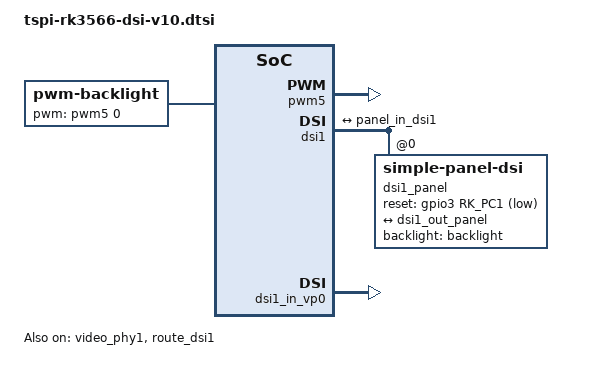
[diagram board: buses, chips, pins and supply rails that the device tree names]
/*********************************************************************
 *           立创开发板不靠卖板赚钱，以培养中国工程师为己任  
 *         泰山派软硬件资料与相关扩展板软硬件资料官网全部开源
 *                      开发板官网：www.lckfb.com            
 *                     立创论坛：oshwhub.com/forum           
 *            关注B站：【立创开发板】，掌握我们的最新动态！  
 *********************************************************************
 * 文件名：tspi-rk3566-dsi-v10.dtsi
 * 描述：mipi 屏幕
 * 更新:
 * 时间          作者           联系           说明
 * 2023-09-13   吴才成    1378913492@qq.com   v1.0.0
 *********************************************************************/
/ {
	backlight: backlight {
		compatible = "pwm-backlight";
		pwms = <&pwm5 0 25000 0>;
		brightness-levels = <
			  0  20  20  21  21  22  22  23
			 23  24  24  25  25  26  26  27
			 27  28  28  29  29  30  30  31
			 31  32  32  33  33  34  34  35
			 35  36  36  37  37  38  38  39
			 40  41  42  43  44  45  46  47
			 48  49  50  51  52  53  54  55
			 56  57  58  59  60  61  62  63
			 64  65  66  67  68  69  70  71
			 72  73  74  75  76  77  78  79
			 80  81  82  83  84  85  86  87
			 88  89  90  91  92  93  94  95
			 96  97  98  99 100 101 102 103
			104 105 106 107 108 109 110 111
			112 113 114 115 116 117 118 119
			120 121 122 123 124 125 126 127
			128 129 130 131 132 133 134 135
			136 137 138 139 140 141 142 143
			144 145 146 147 148 149 150 151
			152 153 154 155 156 157 158 159
			160 161 162 163 164 165 166 167
			168 169 170 171 172 173 174 175
			176 177 178 179 180 181 182 183
			184 185 186 187 188 189 190 191
			192 193 194 195 196 197 198 199
			200 201 202 203 204 205 206 207
			208 209 210 211 212 213 214 215
			216 217 218 219 220 221 222 223
			224 225 226 227 228 229 230 231
			232 233 234 235 236 237 238 239
			240 241 242 243 244 245 246 247
			248 249 250 251 252 253 254 255
		>;
		default-brightness-level = <255>;
	};
};

&pwm5 {
	status = "okay";
};


&pinctrl {
	dsi1 {
		dsi1_rst_gpio: dsi1-rst-gpio {
			rockchip,pins = <3 RK_PC1 RK_FUNC_GPIO &pcfg_pull_none>;
		};
	};
};

/*
 * video_phy1 needs to be enabled
 * when dsi1 is enabled
 */
&dsi1 {
	status = "okay";
};

&dsi1_in_vp0 {
	status = "okay";
};

&dsi1_in_vp1 {
	status = "disabled";
};

&video_phy1 {
	status = "okay";
};

&route_dsi1 {
	status = "okay";//wucaicheng mipi okay
	connect = <&vp0_out_dsi1>;
};

//默认 8寸800x1280
&dsi1 {
	status = "okay";
	rockchip,lane-rate = <480>;
	dsi1_panel: panel@0 {
		status = "okay";
		compatible = "simple-panel-dsi";
		reset-gpios = <&gpio3 RK_PC1 GPIO_ACTIVE_LOW>;
		pinctrl-names = "default";
		pinctrl-0 = <&dsi1_rst_gpio>;
		reg = <0>;
		backlight = <&backlight>;
		reset-delay-ms = <10>;
		enable-delay-ms = <120>;
		prepare-delay-ms = <20>;
		unprepare-delay-ms = <20>;
		disable-delay-ms = <50>;
		dsi,flags = <(MIPI_DSI_MODE_VIDEO | MIPI_DSI_MODE_VIDEO_BURST |
			MIPI_DSI_MODE_LPM | MIPI_DSI_MODE_EOT_PACKET)>;
		dsi,format = <MIPI_DSI_FMT_RGB888>;
		dsi,lanes  = <4>;
		panel-init-sequence = [
			15 00 02 E0 00
			15 00 02 E1 93
			15 00 02 E2 65
			15 00 02 E3 F8
			15 00 02 80 03
			15 00 02 E0 01
			15 00 02 00 00
			15 00 02 01 3C
			15 00 02 03 10
			15 00 02 04 38
			15 00 02 0C 74
			15 00 02 17 00
			15 00 02 18 E7
			15 00 02 19 01
			15 00 02 1A 00
			15 00 02 1B E7
			15 00 02 1C 01
			15 00 02 24 FE
			15 00 02 35 23
			15 00 02 37 09
			15 00 02 38 04
			15 00 02 39 00
			15 00 02 3A 01
			15 00 02 3C 70
			15 00 02 3D FF
			15 00 02 3E FF
			15 00 02 3F 7F
			15 00 02 40 06
			15 00 02 41 A0
			15 00 02 43 1E
			15 00 02 44 0B
			15 00 02 45 28
			15 00 02 55 02
			15 00 02 57 A9
			15 00 02 59 0A
			15 00 02 5A 2D
			15 00 02 5B 19
			15 00 02 5C 15
			15 00 02 5D 7F
			15 00 02 5E 6E
			15 00 02 5F 5F
			15 00 02 60 53
			15 00 02 61 50
			15 00 02 62 41
			15 00 02 63 44
			15 00 02 64 2C
			15 00 02 65 44
			15 00 02 66 42
			15 00 02 67 40
			15 00 02 68 5B
			15 00 02 69 45
			15 00 02 6A 48
			15 00 02 6B 38
			15 00 02 6C 32
			15 00 02 6D 25
			15 00 02 6E 14
			15 00 02 6F 08
			15 00 02 70 7F
			15 00 02 71 6E
			15 00 02 72 5F
			15 00 02 73 53
			15 00 02 74 50
			15 00 02 75 41
			15 00 02 76 44
			15 00 02 77 2C
			15 00 02 78 44
			15 00 02 79 42
			15 00 02 7A 40
			15 00 02 7B 5B
			15 00 02 7C 45
			15 00 02 7D 48
			15 00 02 7E 38
			15 00 02 7F 32
			15 00 02 80 25
			15 00 02 81 14
			15 00 02 82 08
			15 00 02 E0 02
			15 00 02 00 50
			15 00 02 01 5F
			15 00 02 02 5F
			15 00 02 03 52
			15 00 02 04 77
			15 00 02 05 57
			15 00 02 06 5F
			15 00 02 07 4E
			15 00 02 08 4C
			15 00 02 09 5F
			15 00 02 0A 4A
			15 00 02 0B 48
			15 00 02 0C 5F
			15 00 02 0D 46
			15 00 02 0E 44
			15 00 02 0F 40
			15 00 02 10 5F
			15 00 02 11 5F
			15 00 02 12 5F
			15 00 02 13 5F
			15 00 02 14 5F
			15 00 02 15 5F
			15 00 02 16 51
			15 00 02 17 5F
			15 00 02 18 5F
			15 00 02 19 53
			15 00 02 1A 77
			15 00 02 1B 57
			15 00 02 1C 5F
			15 00 02 1D 4F
			15 00 02 1E 4D
			15 00 02 1F 5F
			15 00 02 20 4B
			15 00 02 21 49
			15 00 02 22 5F
			15 00 02 23 47
			15 00 02 24 45
			15 00 02 25 41
			15 00 02 26 5F
			15 00 02 27 5F
			15 00 02 28 5F
			15 00 02 29 5F
			15 00 02 2A 5F
			15 00 02 2B 5F
			15 00 02 2C 01
			15 00 02 2D 1F
			15 00 02 2E 1F
			15 00 02 2F 13
			15 00 02 30 17
			15 00 02 31 17
			15 00 02 32 1F
			15 00 02 33 0D
			15 00 02 34 0F
			15 00 02 35 1F
			15 00 02 36 05
			15 00 02 37 07
			15 00 02 38 1F
			15 00 02 39 09
			15 00 02 3A 0B
			15 00 02 3B 11
			15 00 02 3C 1F
			15 00 02 3D 1F
			15 00 02 3E 1F
			15 00 02 3F 1F
			15 00 02 40 1F
			15 00 02 41 1F
			15 00 02 42 00
			15 00 02 43 1F
			15 00 02 44 1F
			15 00 02 45 12
			15 00 02 46 17
			15 00 02 47 17
			15 00 02 48 1F
			15 00 02 49 0C
			15 00 02 4A 0E
			15 00 02 4B 1F
			15 00 02 4C 04
			15 00 02 4D 06
			15 00 02 4E 1F
			15 00 02 4F 08
			15 00 02 50 0A
			15 00 02 51 10
			15 00 02 52 1F
			15 00 02 53 1F
			15 00 02 54 1F
			15 00 02 55 1F
			15 00 02 56 1F
			15 00 02 57 1F
			15 00 02 58 40
			15 00 02 5B 10
			15 00 02 5C 06
			15 00 02 5D 40
			15 00 02 5E 00
			15 00 02 5F 00
			15 00 02 60 40
			15 00 02 61 03
			15 00 02 62 04
			15 00 02 63 6C
			15 00 02 64 6C
			15 00 02 65 75
			15 00 02 66 08
			15 00 02 67 B4
			15 00 02 68 08
			15 00 02 69 6C
			15 00 02 6A 6C
			15 00 02 6B 0C
			15 00 02 6D 00
			15 00 02 6E 00
			15 00 02 6F 88
			15 00 02 75 BB
			15 00 02 76 00
			15 00 02 77 05
			15 00 02 78 2A
			15 00 02 E0 04
			15 00 02 00 0E
			15 00 02 02 B3
			15 00 02 09 60
			15 00 02 0E 48
			15 00 02 E0 00
			05 fa 01 11
			05 32 01 29
		];

		panel-exit-sequence = [
			05 00 01 28
			05 00 01 10
		];

		disp_timings1: display-timings {
			native-mode = <&dsi1_timing0>;
			dsi1_timing0: timing0 {
				clock-frequency = <66000000>;
				hactive = <800>;
				vactive = <1280>;
				hfront-porch = <18>;
				hsync-len = <12>;
				hback-porch = <18>;
				vfront-porch = <24>;
				vsync-len = <4>;
				vback-porch = <12>;
				hsync-active = <0>;
				vsync-active = <0>;
				de-active = <0>;
				pixelclk-active = <1>;
			};
		};

		ports {
			#address-cells = <1>;
			#size-cells = <0>;

			port@0 {
				reg = <0>;
				panel_in_dsi1: endpoint {
					remote-endpoint = <&dsi1_out_panel>;
				};
			};
		};
	};

	ports {
		#address-cells = <1>;
		#size-cells = <0>;

		port@1 {
			reg = <1>;
			dsi1_out_panel: endpoint {
				remote-endpoint = <&panel_in_dsi1>;
			};
		};
	};

};

// &dsi1 {
// 	status = "okay";
// 	rockchip,lane-rate = <1000>;
// 	dsi1_panel: panel@0 {
// 		status = "okay";
// 		compatible = "simple-panel-dsi";
// 		reset-gpios = <&gpio3 RK_PC1 GPIO_ACTIVE_LOW>;
// 		pinctrl-names = "default";
// 		pinctrl-0 = <&dsi1_rst_gpio>;
// 		reg = <0>;
// 		backlight = <&backlight>;
// 		reset-delay-ms = <100>;
// 		enable-delay-ms = <120>;
// 		prepare-delay-ms = <20>;
// 		unprepare-delay-ms = <20>;
// 		disable-delay-ms = <100>;
// 		dsi,flags = <(MIPI_DSI_MODE_VIDEO | MIPI_DSI_MODE_VIDEO_BURST |
// 			MIPI_DSI_MODE_LPM | MIPI_DSI_MODE_EOT_PACKET)>;
// 		dsi,format = <MIPI_DSI_FMT_RGB888>;
// 		dsi,lanes  = <4>;
// 		panel-init-sequence = [
// 			15 00 02 B0 01
// 			15 00 02 C3 4F
// 			15 00 02 C4 40
// 			15 00 02 C5 40
// 			15 00 02 C6 40
// 			15 00 02 C7 40
// 			15 00 02 C8 4D
// 			15 00 02 C9 52
// 			15 00 02 CA 51
// 			15 00 02 CD 5D
// 			15 00 02 CE 5B
// 			15 00 02 CF 4B
// 			15 00 02 D0 49
// 			15 00 02 D1 47
// 			15 00 02 D2 45
// 			15 00 02 D3 41
// 			15 00 02 D7 50
// 			15 00 02 D8 40
// 			15 00 02 D9 40
// 			15 00 02 DA 40
// 			15 00 02 DB 40
// 			15 00 02 DC 4E
// 			15 00 02 DD 52
// 			15 00 02 DE 51
// 			15 00 02 E1 5E
// 			15 00 02 E2 5C
// 			15 00 02 E3 4C
// 			15 00 02 E4 4A
// 			15 00 02 E5 48
// 			15 00 02 E6 46
// 			15 00 02 E7 42
// 			15 00 02 B0 03
// 			15 00 02 BE 03
// 			15 00 02 CC 44
// 			15 00 02 C8 07
// 			15 00 02 C9 05
// 			15 00 02 CA 42
// 			15 00 02 CD 3E
// 			15 00 02 CF 60
// 			15 00 02 D2 04
// 			15 00 02 D3 04
// 			15 00 02 D4 01
// 			15 00 02 D5 00
// 			15 00 02 D6 03
// 			15 00 02 D7 04
// 			15 00 02 D9 01
// 			15 00 02 DB 01
// 			15 00 02 E4 F0
// 			15 00 02 E5 0A
// 			15 00 02 B0 00
// 			15 00 02 B1 08
// 			15 00 02 BD 54
// 			15 00 02 C2 06
// 			15 00 02 C4 0B
// 			15 00 02 B0 02
// 			15 00 02 C0 00
// 			15 00 02 C1 0A
// 			15 00 02 C2 20
// 			15 00 02 C3 24
// 			15 00 02 C4 23
// 			15 00 02 C5 29
// 			15 00 02 C6 23
// 			15 00 02 C7 1C
// 			15 00 02 C8 19
// 			15 00 02 C9 17
// 			15 00 02 CA 17
// 			15 00 02 CB 18
// 			15 00 02 CC 1A
// 			15 00 02 CD 1E
// 			15 00 02 CE 20
// 			15 00 02 CF 23
// 			15 00 02 D0 07
// 			15 00 02 D1 00
// 			15 00 02 D2 00
// 			15 00 02 D3 0A
// 			15 00 02 D4 13
// 			15 00 02 D5 1C
// 			15 00 02 D6 1A
// 			15 00 02 D7 13
// 			15 00 02 D8 17
// 			15 00 02 D9 1C
// 			15 00 02 DA 19
// 			15 00 02 DB 17
// 			15 00 02 DC 17
// 			15 00 02 DD 18
// 			15 00 02 DE 1A
// 			15 00 02 DF 1E
// 			15 00 02 E0 20
// 			15 00 02 E1 23
// 			15 00 02 E2 07
// 			05 78 01 11
// 			05 14 01 29
// 		];

// 		panel-exit-sequence = [
// 			05 00 01 28
// 			05 00 01 10
// 		];

// 		disp_timings1: display-timings {
// 			native-mode = <&dsi1_timing0>;
// 			dsi1_timing0: timing0 {
// 				clock-frequency = <156000000>;
// 				hactive = <1200 >;
// 				vactive = <1920>;
// 				hfront-porch = <42>;
// 				hsync-len = <10>;
// 				hback-porch = <32>;
// 				vfront-porch = <35>;
// 				vsync-len = <4>;
// 				vback-porch = <30>;
// 				hsync-active = <0>;
// 				vsync-active = <0>;
// 				de-active = <0>;
// 				pixelclk-active = <0>;
// 			};
// 		};

// 		ports {
// 			#address-cells = <1>;
// 			#size-cells = <0>;

// 			port@0 {
// 				reg = <0>;
// 				panel_in_dsi1: endpoint {
// 					remote-endpoint = <&dsi1_out_panel>;
// 				};
// 			};
// 		};
// 	};

// 	ports {
// 		#address-cells = <1>;
// 		#size-cells = <0>;

// 		port@1 {
// 			reg = <1>;
// 			dsi1_out_panel: endpoint {
// 				remote-endpoint = <&panel_in_dsi1>;
// 			};
// 		};
// 	};

// };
